VERSION ""

NS_ :

BS_:

BU_: BMU BMS VCU

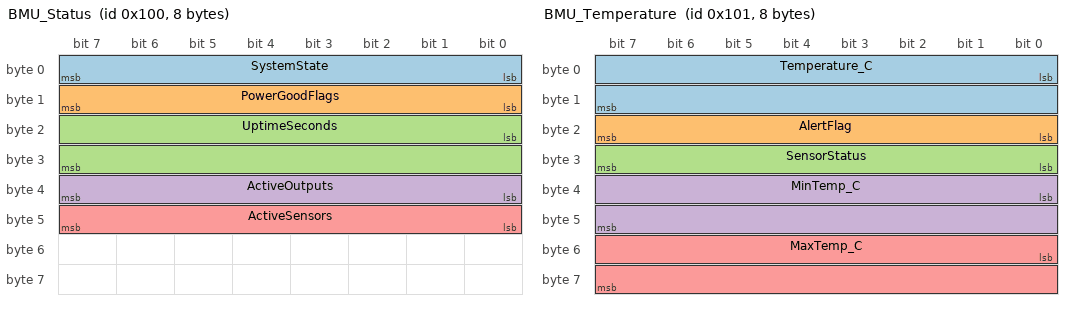
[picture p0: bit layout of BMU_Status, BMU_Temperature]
BO_ 256 BMU_Status: 8 BMU
 SG_ SystemState : 0|8@1+ (1,0) [0|3] "" BMS,VCU
 SG_ PowerGoodFlags : 8|8@1+ (1,0) [0|255] "" BMS,VCU
 SG_ UptimeSeconds : 16|16@1+ (1,0) [0|65535] "s" BMS,VCU
 SG_ ActiveOutputs : 32|8@1+ (1,0) [0|20] "" BMS,VCU
 SG_ ActiveSensors : 40|8@1+ (1,0) [0|10] "" BMS,VCU

BO_ 257 BMU_Temperature: 8 BMU
 SG_ Temperature_C : 0|16@1- (0.01,0) [-100|100] "C" BMS,VCU
 SG_ AlertFlag : 16|8@1+ (1,0) [0|1] "" BMS,VCU
 SG_ SensorStatus : 24|8@1+ (1,0) [0|255] "" BMS,VCU
 SG_ MinTemp_C : 32|16@1- (0.01,0) [-100|100] "C" BMS,VCU
 SG_ MaxTemp_C : 48|16@1- (0.01,0) [-100|100] "C" BMS,VCU

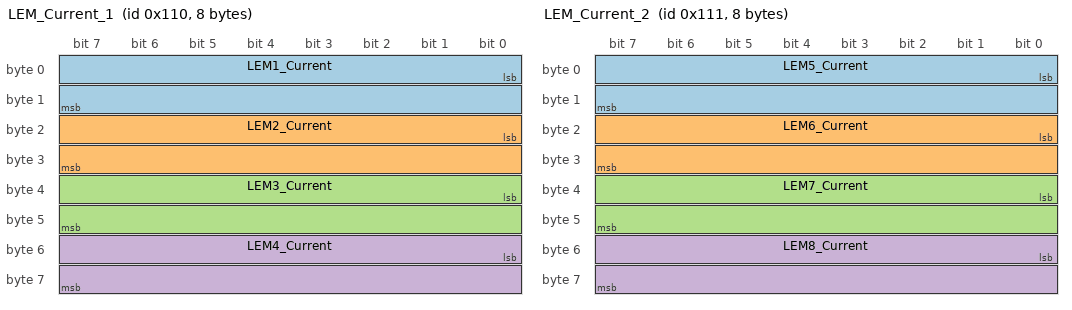
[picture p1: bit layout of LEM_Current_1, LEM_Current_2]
BO_ 272 LEM_Current_1: 8 BMU
 SG_ LEM1_Current : 0|16@1- (0.001,0) [-200|200] "A" BMS,VCU
 SG_ LEM2_Current : 16|16@1- (0.001,0) [-200|200] "A" BMS,VCU
 SG_ LEM3_Current : 32|16@1- (0.001,0) [-200|200] "A" BMS,VCU
 SG_ LEM4_Current : 48|16@1- (0.001,0) [-200|200] "A" BMS,VCU

BO_ 273 LEM_Current_2: 8 BMU
 SG_ LEM5_Current : 0|16@1- (0.001,0) [-200|200] "A" BMS,VCU
 SG_ LEM6_Current : 16|16@1- (0.001,0) [-200|200] "A" BMS,VCU
 SG_ LEM7_Current : 32|16@1- (0.001,0) [-200|200] "A" BMS,VCU
 SG_ LEM8_Current : 48|16@1- (0.001,0) [-200|200] "A" BMS,VCU

BO_ 274 LEM_Current_3: 8 BMU
 SG_ LEM9_Current : 0|16@1- (0.001,0) [-200|200] "A" BMS,VCU
 SG_ LEM10_Current : 16|16@1- (0.001,0) [-200|200] "A" BMS,VCU

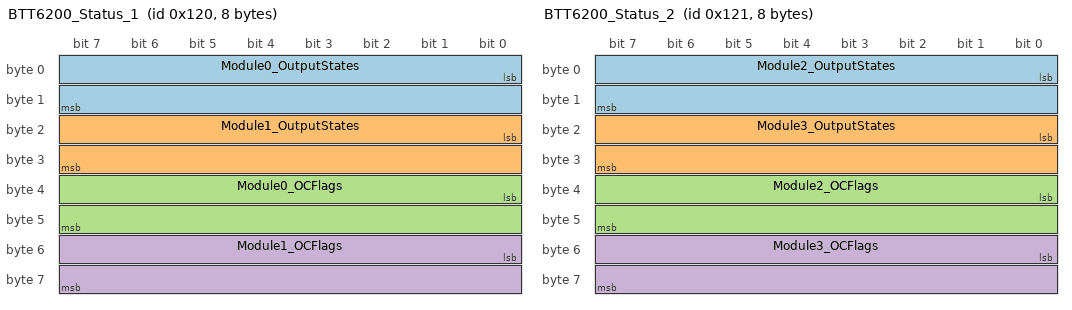
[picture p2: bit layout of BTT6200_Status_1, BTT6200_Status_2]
BO_ 288 BTT6200_Status_1: 8 BMU
 SG_ Module0_OutputStates : 0|16@1+ (1,0) [0|15] "" BMS,VCU
 SG_ Module1_OutputStates : 16|16@1+ (1,0) [0|15] "" BMS,VCU
 SG_ Module0_OCFlags : 32|16@1+ (1,0) [0|15] "" BMS,VCU
 SG_ Module1_OCFlags : 48|16@1+ (1,0) [0|15] "" BMS,VCU

BO_ 289 BTT6200_Status_2: 8 BMU
 SG_ Module2_OutputStates : 0|16@1+ (1,0) [0|15] "" BMS,VCU
 SG_ Module3_OutputStates : 16|16@1+ (1,0) [0|15] "" BMS,VCU
 SG_ Module2_OCFlags : 32|16@1+ (1,0) [0|15] "" BMS,VCU
 SG_ Module3_OCFlags : 48|16@1+ (1,0) [0|15] "" BMS,VCU

BO_ 290 BTT6200_Status_3: 8 BMU
 SG_ Module4_OutputStates : 0|16@1+ (1,0) [0|15] "" BMS,VCU
 SG_ Module4_OCFlags : 16|16@1+ (1,0) [0|15] "" BMS,VCU

BO_ 304 FRAM_Statistics: 8 BMU
 SG_ SampleCount : 0|32@1+ (1,0) [0|4294967295] "" BMS,VCU
 SG_ AlertCount : 32|32@1+ (1,0) [0|4294967295] "" BMS,VCU

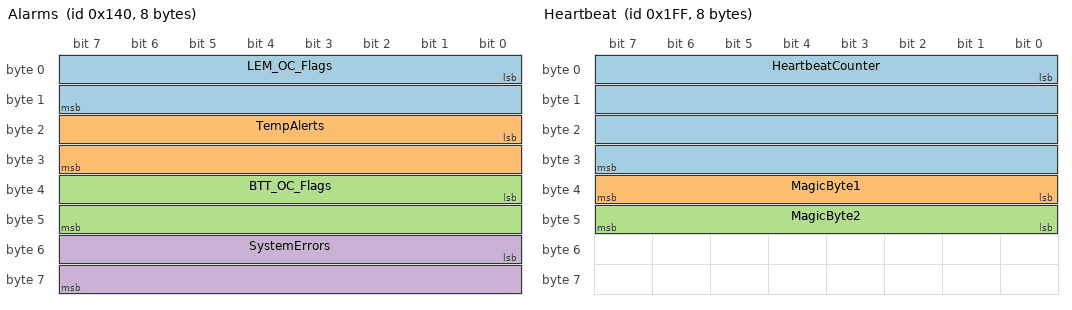
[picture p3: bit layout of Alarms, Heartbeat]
BO_ 320 Alarms: 8 BMU
 SG_ LEM_OC_Flags : 0|16@1+ (1,0) [0|1023] "" BMS,VCU
 SG_ TempAlerts : 16|16@1+ (1,0) [0|65535] "" BMS,VCU
 SG_ BTT_OC_Flags : 32|16@1+ (1,0) [0|65535] "" BMS,VCU
 SG_ SystemErrors : 48|16@1+ (1,0) [0|65535] "" BMS,VCU

BO_ 511 Heartbeat: 8 BMU
 SG_ HeartbeatCounter : 0|32@1+ (1,0) [0|4294967295] "" BMS,VCU
 SG_ MagicByte1 : 32|8@1+ (1,0) [0|255] "" BMS,VCU
 SG_ MagicByte2 : 40|8@1+ (1,0) [0|255] "" BMS,VCU

CM_ BU_ BMU "Battery Management Unit - Main Controller";
CM_ BU_ BMS "Battery Management System - External";
CM_ BU_ VCU "Vehicle Control Unit";
CM_ BO_ 256 "BMU System Status Message - 10Hz";
CM_ BO_ 257 "Temperature Sensor Data - 1Hz";
CM_ BO_ 272 "LEM Current Sensors 1-4 - 10Hz";
CM_ BO_ 273 "LEM Current Sensors 5-8 - 10Hz";
CM_ BO_ 274 "LEM Current Sensors 9-10 - 10Hz";
CM_ BO_ 288 "BTT6200 Output Status Modules 0-1 - 5Hz";
CM_ BO_ 289 "BTT6200 Output Status Modules 2-3 - 5Hz";
CM_ BO_ 290 "BTT6200 Output Status Module 4 - 5Hz";
CM_ BO_ 304 "FRAM Memory Statistics - 1Hz";
CM_ BO_ 320 "System Alarms and Errors - On Change";
CM_ BO_ 511 "Heartbeat Message - 1Hz";
CM_ SG_ 256 SystemState "0=Init, 1=Normal, 2=Warning, 3=Error";
CM_ SG_ 256 PowerGoodFlags "Bit0=5V, Bit1=3V3A, Bit2=24V";
CM_ SG_ 257 Temperature_C "Current temperature from TMP1075 sensor";
CM_ SG_ 257 AlertFlag "1=Temperature below 0C";
CM_ SG_ 272 LEM1_Current "LEM sensor 1 current measurement in Amperes";
CM_ SG_ 272 LEM2_Current "LEM sensor 2 current measurement in Amperes";
CM_ SG_ 272 LEM3_Current "LEM sensor 3 current measurement in Amperes";
CM_ SG_ 272 LEM4_Current "LEM sensor 4 current measurement in Amperes";
CM_ SG_ 320 LEM_OC_Flags "LEM Overcurrent flags: Bit0=LEM1, Bit1=LEM2, etc";
CM_ SG_ 320 SystemErrors "System error flags bitfield";
BA_DEF_ "BusType" STRING ;
BA_DEF_ BO_ "GenMsgCycleTime" INT 0 10000;
BA_DEF_DEF_ "BusType" "CAN";
BA_DEF_DEF_ BO_ "GenMsgCycleTime" 0;
BA_ "GenMsgCycleTime" BO_ 256 100;
BA_ "GenMsgCycleTime" BO_ 257 1000;
BA_ "GenMsgCycleTime" BO_ 272 100;
BA_ "GenMsgCycleTime" BO_ 273 100;
BA_ "GenMsgCycleTime" BO_ 274 100;
BA_ "GenMsgCycleTime" BO_ 288 200;
BA_ "GenMsgCycleTime" BO_ 289 200;
BA_ "GenMsgCycleTime" BO_ 290 200;
BA_ "GenMsgCycleTime" BO_ 304 1000;
BA_ "GenMsgCycleTime" BO_ 320 0;
BA_ "GenMsgCycleTime" BO_ 511 1000;
VAL_ 256 SystemState 0 "Init" 1 "Normal" 2 "Warning" 3 "Error" ;
VAL_ 257 AlertFlag 0 "OK" 1 "LowTempAlert" ;
